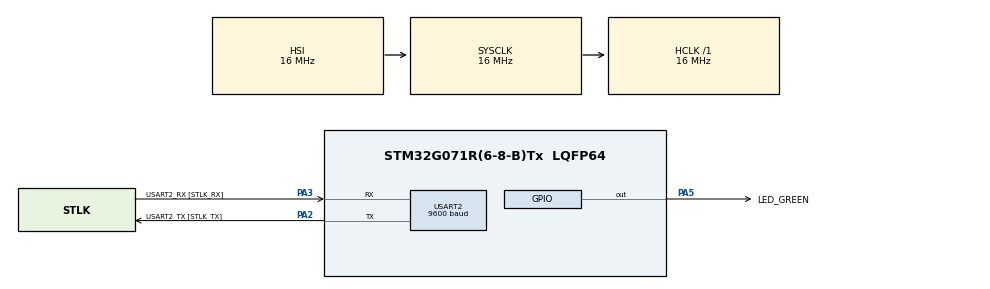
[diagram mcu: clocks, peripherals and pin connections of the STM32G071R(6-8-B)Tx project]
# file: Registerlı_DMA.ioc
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Dma.Request0=USART2_RX
Dma.USART2_RX.0.Direction=DMA_PERIPH_TO_MEMORY
Dma.USART2_RX.0.EventEnable=DISABLE
Dma.USART2_RX.0.Instance=DMA1_Channel1
Dma.USART2_RX.0.MemDataAlignment=DMA_MDATAALIGN_BYTE
Dma.USART2_RX.0.MemInc=DMA_MINC_ENABLE
Dma.USART2_RX.0.Mode=DMA_NORMAL
Dma.USART2_RX.0.PeriphDataAlignment=DMA_PDATAALIGN_BYTE
Dma.USART2_RX.0.PeriphInc=DMA_PINC_DISABLE
Dma.USART2_RX.0.Polarity=HAL_DMAMUX_REQ_GEN_RISING
Dma.USART2_RX.0.Priority=DMA_PRIORITY_LOW
Dma.USART2_RX.0.RequestNumber=1
Dma.USART2_RX.0.SignalID=NONE
Dma.USART2_RX.0.SyncEnable=DISABLE
Dma.USART2_RX.0.SyncPolarity=HAL_DMAMUX_SYNC_NO_EVENT
Dma.USART2_RX.0.SyncRequestNumber=1
Dma.USART2_RX.0.SyncSignalID=NONE
Mcu.Family=STM32G0
Mcu.Name=STM32G071R(6-8-B)Tx
Mcu.Package=LQFP64
NVIC.DMA1_Channel1_IRQn=true\:0\:0\:false\:false\:true\:false\:true\:true
NVIC.USART2_IRQn=true\:0\:0\:false\:false\:true\:true\:true\:true
PA13.GPIO_Label=TMS
PA13.Mode=Serial_Wire
PA13.Signal=SYS_SWDIO
PA14-BOOT0.GPIO_Label=TCK
PA14-BOOT0.Mode=Serial_Wire
PA14-BOOT0.Signal=SYS_SWCLK
PA2.GPIO_Label=USART2_TX [STLK_TX]
PA2.GPIO_PuPd=GPIO_PULLUP
PA2.Mode=Asynchronous
PA2.Signal=USART2_TX
PA3.GPIO_Label=USART2_RX [STLK_RX]
PA3.GPIO_PuPd=GPIO_PULLUP
PA3.Mode=Asynchronous
PA3.Signal=USART2_RX
PA5.GPIO_Label=LED_GREEN
PA5.GPIO_Speed=GPIO_SPEED_FREQ_HIGH
PA5.Signal=GPIO_Output
PC13.Mode=SYS_WakeUp1
PC13.Signal=SYS_WKUP2
PC14-OSC32_IN\ (PC14).Mode=LSE-External-Oscillator
PC14-OSC32_IN\ (PC14).Signal=RCC_OSC32_IN
PC15-OSC32_OUT\ (PC15).Mode=LSE-External-Oscillator
PC15-OSC32_OUT\ (PC15).Signal=RCC_OSC32_OUT
PF0-OSC_IN\ (PF0).GPIO_Label=MCO
PF0-OSC_IN\ (PF0).Mode=HSE-External-Clock-Source
PF0-OSC_IN\ (PF0).Signal=RCC_OSC_IN
ProjectManager.HeapSize=0x200
ProjectManager.StackSize=0x400
ProjectManager.TargetToolchain=STM32CubeIDE
RCC.AHBFreq_Value=16000000
RCC.CortexFreq_Value=16000000
RCC.EXTERNAL_CLOCK_VALUE=12288000
RCC.HCLKFreq_Value=16000000
RCC.HSE_VALUE=8000000
RCC.HSI_VALUE=16000000
RCC.SYSCLKFreq_VALUE=16000000
RCC.VCOOutputFreq_Value=128000000
USART2.BaudRate=9600
USART2.VirtualMode-Asynchronous=VM_ASYNC
board=NUCLEO-G071RB

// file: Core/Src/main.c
/* USER CODE BEGIN Header */
/**
  ******************************************************************************
  * @file           : main.c
  * @brief          : Main program body
  ******************************************************************************
  * @attention
  *
  * Copyright (c) 2024 STMicroelectronics.
  * All rights reserved.
  *
  * This software is licensed under terms that can be found in the LICENSE file
  * in the root directory of this software component.
  * If no LICENSE file comes with this software, it is provided AS-IS.
  *
  ******************************************************************************
  */
/* USER CODE END Header */
#include "main.h"

UART_HandleTypeDef huart2;
DMA_HandleTypeDef hdma_usart2_rx;

void SystemClock_Config(void);
static void MX_GPIO_Init(void);
static void MX_DMA_Init(void);
static void MX_USART2_UART_Init(void);

/* USER CODE BEGIN 0 */
uint8_t RxRawData[32];
uint8_t RxData[32];

int isSizeRxed = 0 ;
uint16_t size = 0;
int rxsize=sizeof(RxRawData);
uint16_t rxlen;

//uint16_t rxlen=4;

/*
	if(isSizeRxed == 0){

		size = ((RxData[0]-48)*1000)+((RxData[1]-48)*100)+((RxData[2]-48)*10)+((RxData[3]-48));
		isSizeRxed = 1;
		HAL_UART_Receive_DMA(&huart2, RxData, rxlen);

	}
	else if (isSizeRxed == 1){
		isSizeRxed= 0;
		HAL_UART_Receive_DMA(&huart2, RxData, 4);
	}
*/

/* USER CODE END 0 */

int main(void)
{

  /* MCU Configuration--------------------------------------------------------*/

  /* Reset of all peripherals, Initializes the Flash interface and the Systick. */
  HAL_Init();

  /* Configure the system clock */
  SystemClock_Config();

  /* USER CODE BEGIN SysInit */
  /*
	for( int i=0;i<sizeof(RxRawData);i++ ){
		RxData[i]=0x00;
		RxRawData[i]=0;
	}
	*/
  /* USER CODE END SysInit */

  /* Initialize all configured peripherals */

  MX_GPIO_Init();
  MX_DMA_Init();
  MX_USART2_UART_Init();
  /* USER CODE BEGIN 2 */

  HAL_UART_Receive_IT(&huart2, RxRawData, sizeof(RxRawData));

  //HAL_UART_Receive_DMA(&huart2, RxData, 4);
  /* USER CODE END 2 */

  /* Infinite loop */
  while (1)
  {
	  HAL_GPIO_TogglePin(GPIOA, GPIO_PIN_5);
	  HAL_Delay(500);
  }
}

void SystemClock_Config(void)
{
  RCC_OscInitTypeDef RCC_OscInitStruct = {0};
  RCC_ClkInitTypeDef RCC_ClkInitStruct = {0};

  /** Configure the main internal regulator output voltage
  */
  HAL_PWREx_ControlVoltageScaling(PWR_REGULATOR_VOLTAGE_SCALE1);

  /** Initializes the RCC Oscillators according to the specified parameters
  * in the RCC_OscInitTypeDef structure.
  */
  RCC_OscInitStruct.OscillatorType = RCC_OSCILLATORTYPE_HSI;
  RCC_OscInitStruct.HSIState = RCC_HSI_ON;
  RCC_OscInitStruct.HSIDiv = RCC_HSI_DIV1;
  RCC_OscInitStruct.HSICalibrationValue = RCC_HSICALIBRATION_DEFAULT;
  RCC_OscInitStruct.PLL.PLLState = RCC_PLL_NONE;
  if (HAL_RCC_OscConfig(&RCC_OscInitStruct) != HAL_OK)
  {
    Error_Handler();
  }

  /** Initializes the CPU, AHB and APB buses clocks
  */
  RCC_ClkInitStruct.ClockType = RCC_CLOCKTYPE_HCLK|RCC_CLOCKTYPE_SYSCLK
                              |RCC_CLOCKTYPE_PCLK1;
  RCC_ClkInitStruct.SYSCLKSource = RCC_SYSCLKSOURCE_HSI;
  RCC_ClkInitStruct.AHBCLKDivider = RCC_SYSCLK_DIV1;
  RCC_ClkInitStruct.APB1CLKDivider = RCC_HCLK_DIV1;

  if (HAL_RCC_ClockConfig(&RCC_ClkInitStruct, FLASH_LATENCY_0) != HAL_OK)
  {
    Error_Handler();
  }
}

void MX_USART2_UART_Init2() {
	USART2->CR1 &= ~(USART_CR1_UE); //Disables USART2 by clearing the UE (USART enable) bit in the control register 1 (CR1).
    USART2->RTOR = (20<<USART_RTOR_RTO_Pos); // Set the receiver timeout value to 20 bit. RTOR-> Receiver Timeout Register
    USART2->ICR |= USART_ICR_RTOCF;   //Clear the receiver timeout ICR->Interrupt Clear Register
    USART2->CR1 |= USART_CR1_RTOIE;	//Enable the reiver timeout
    USART2->CR2 |= USART_CR2_RTOEN;	//Enabletimeout

	USART2->CR3 |= USART_CR3_DMAR; //Re-enables USART2 by setting the UE bit in CR1.

    USART2->CR1 |= USART_CR1_UE; //Re-enables USART2 by setting the UE bit in CR1.

    NVIC_SetPriority(USART2_IRQn, 0);  //Set priority of the usart2 interrupt in nvıc-> Nested Vectored Interrupt Controller
    NVIC_EnableIRQ(USART2_IRQn); //Enable interrupt in nvıc
}

static void MX_USART2_UART_Init(void)
{

  huart2.Instance = USART2;
  huart2.Init.BaudRate = 9600;
  huart2.Init.WordLength = UART_WORDLENGTH_8B;
  huart2.Init.StopBits = UART_STOPBITS_1;
  huart2.Init.Parity = UART_PARITY_NONE;
  huart2.Init.Mode = UART_MODE_TX_RX;
  huart2.Init.HwFlowCtl = UART_HWCONTROL_NONE;
  huart2.Init.OverSampling = UART_OVERSAMPLING_16;
  huart2.Init.OneBitSampling = UART_ONE_BIT_SAMPLE_DISABLE;
  huart2.Init.ClockPrescaler = UART_PRESCALER_DIV1;
  huart2.AdvancedInit.AdvFeatureInit = UART_ADVFEATURE_NO_INIT;

  if (HAL_UART_Init(&huart2) != HAL_OK)
  {
    Error_Handler();
  }
  if (HAL_UARTEx_SetTxFifoThreshold(&huart2, UART_TXFIFO_THRESHOLD_1_8) != HAL_OK)
  {
    Error_Handler();
  }
  if (HAL_UARTEx_SetRxFifoThreshold(&huart2, UART_RXFIFO_THRESHOLD_1_8) != HAL_OK)
  {
    Error_Handler();
  }
  if (HAL_UARTEx_DisableFifoMode(&huart2) != HAL_OK)
  {
    Error_Handler();
  }
  /* USER CODE BEGIN USART2_Init 2 */
  MX_USART2_UART_Init2();

  /* USER CODE END USART2_Init 2 */

}

static void MX_DMA_Init(void)
{

  /* DMA controller clock enable */
  __HAL_RCC_DMA1_CLK_ENABLE();

	DMA1_Channel1->CCR &= ~(
		  DMA_CCR_EN
		| DMA_CCR_MEM2MEM
		| DMA_CCR_PL
		| DMA_CCR_MSIZE
		| DMA_CCR_PSIZE
		| DMA_CCR_PINC
		| DMA_CCR_CIRC
		| DMA_CCR_DIR
	);
	DMA1_Channel1->CCR |= 2<<DMA_CCR_PL_Pos ;
	DMA1_Channel1->CCR |= DMA_CCR_MINC;// | DMA_CCR_CIRC;

	DMAMUX1_Channel0->CCR &= ~(DMAMUX_CxCR_DMAREQ_ID);
	DMAMUX1_Channel0->CCR = 52;

	//uint16_t rxlen = sizeof(RxRawData) - DMA1_Channel1->CNDTR;   //CAlculate the received data lenght
	DMA1_Channel1->CPAR = (uint32_t)&USART2->RDR;		// Set the memory adress for DMA transfer
	DMA1_Channel1->CMAR = (uint32_t)&RxRawData[0];		// Set the memory adress for DMA transfer
	DMA1_Channel1->CNDTR = (uint16_t)sizeof(RxRawData);	//Set the number of data items to transfer
	DMA1_Channel1->CCR |= DMA_CCR_EN;

  /* DMA interrupt init */
  /* DMA1_Channel1_IRQn interrupt configuration */
  HAL_NVIC_SetPriority(DMA1_Channel1_IRQn, 0, 0);
  HAL_NVIC_EnableIRQ(DMA1_Channel1_IRQn);

}

static void MX_GPIO_Init(void)
{
  GPIO_InitTypeDef GPIO_InitStruct = {0};

  /* GPIO Ports Clock Enable */
  __HAL_RCC_GPIOC_CLK_ENABLE();
  __HAL_RCC_GPIOF_CLK_ENABLE();
  __HAL_RCC_GPIOA_CLK_ENABLE();

  /*Configure GPIO pin Output Level */
  HAL_GPIO_WritePin(LED_GREEN_GPIO_Port, LED_GREEN_Pin, GPIO_PIN_RESET);

  /*Configure GPIO pin : LED_GREEN_Pin */
  GPIO_InitStruct.Pin = LED_GREEN_Pin;
  GPIO_InitStruct.Mode = GPIO_MODE_OUTPUT_PP;
  GPIO_InitStruct.Pull = GPIO_NOPULL;
  GPIO_InitStruct.Speed = GPIO_SPEED_FREQ_HIGH;
  HAL_GPIO_Init(LED_GREEN_GPIO_Port, &GPIO_InitStruct);

}

void Error_Handler(void)
{
  __disable_irq();
  while (1)
  {
  }
}
